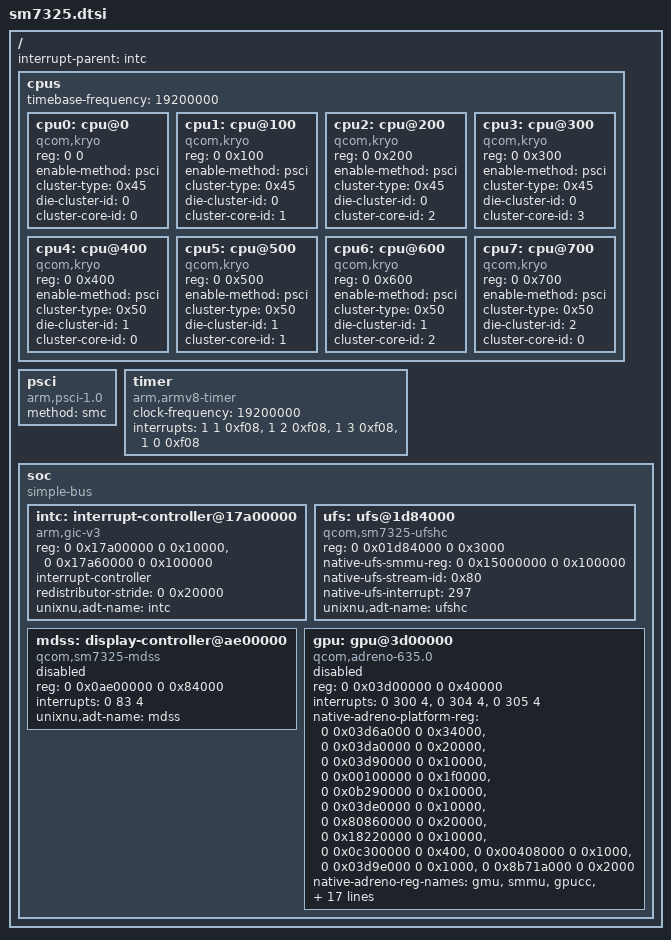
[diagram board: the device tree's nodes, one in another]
// SPDX-License-Identifier: BSD-2-Clause-Patent

/ {
    #address-cells = <2>;
    #size-cells = <2>;
    interrupt-parent = <&intc>;

    cpus {
        #address-cells = <2>;
        #size-cells = <0>;
        timebase-frequency = <19200000>;

        cpu0: cpu@0 {
            device_type = "cpu";
            compatible = "qcom,kryo";
            reg = <0 0>;
            enable-method = "psci";
            cluster-type = <0x45>;
            die-cluster-id = <0>;
            cluster-core-id = <0>;
        };

        cpu1: cpu@100 {
            device_type = "cpu";
            compatible = "qcom,kryo";
            reg = <0 0x100>;
            enable-method = "psci";
            cluster-type = <0x45>;
            die-cluster-id = <0>;
            cluster-core-id = <1>;
        };

        cpu2: cpu@200 {
            device_type = "cpu";
            compatible = "qcom,kryo";
            reg = <0 0x200>;
            enable-method = "psci";
            cluster-type = <0x45>;
            die-cluster-id = <0>;
            cluster-core-id = <2>;
        };

        cpu3: cpu@300 {
            device_type = "cpu";
            compatible = "qcom,kryo";
            reg = <0 0x300>;
            enable-method = "psci";
            cluster-type = <0x45>;
            die-cluster-id = <0>;
            cluster-core-id = <3>;
        };

        cpu4: cpu@400 {
            device_type = "cpu";
            compatible = "qcom,kryo";
            reg = <0 0x400>;
            enable-method = "psci";
            cluster-type = <0x50>;
            die-cluster-id = <1>;
            cluster-core-id = <0>;
        };

        cpu5: cpu@500 {
            device_type = "cpu";
            compatible = "qcom,kryo";
            reg = <0 0x500>;
            enable-method = "psci";
            cluster-type = <0x50>;
            die-cluster-id = <1>;
            cluster-core-id = <1>;
        };

        cpu6: cpu@600 {
            device_type = "cpu";
            compatible = "qcom,kryo";
            reg = <0 0x600>;
            enable-method = "psci";
            cluster-type = <0x50>;
            die-cluster-id = <1>;
            cluster-core-id = <2>;
        };

        cpu7: cpu@700 {
            device_type = "cpu";
            compatible = "qcom,kryo";
            reg = <0 0x700>;
            enable-method = "psci";
            cluster-type = <0x50>;
            die-cluster-id = <2>;
            cluster-core-id = <0>;
        };
    };

    psci {
        compatible = "arm,psci-1.0";
        method = "smc";
    };

    timer {
        compatible = "arm,armv8-timer";
        clock-frequency = <19200000>;
        interrupts = <1 1 0xf08>, <1 2 0xf08>, <1 3 0xf08>, <1 0 0xf08>;
    };

    soc {
        compatible = "simple-bus";
        #address-cells = <2>;
        #size-cells = <2>;
        ranges;

        intc: interrupt-controller@17a00000 {
            compatible = "arm,gic-v3";
            reg = <0 0x17a00000 0 0x10000>, <0 0x17a60000 0 0x100000>;
            #interrupt-cells = <3>;
            interrupt-controller;
            redistributor-stride = <0 0x20000>;
            unixnu,adt-name = "intc";
        };

        ufs: ufs@1d84000 {
            compatible = "qcom,sm7325-ufshc";
            reg = <0 0x01d84000 0 0x3000>;
            native-ufs-smmu-reg = <0 0x15000000 0 0x100000>;
            native-ufs-stream-id = <0x80>;
            native-ufs-interrupt = <297>;
            unixnu,adt-name = "ufshc";
        };

        mdss: display-controller@ae00000 {
            compatible = "qcom,sm7325-mdss";
            reg = <0 0x0ae00000 0 0x84000>;
            interrupts = <0 83 4>;
            unixnu,adt-name = "mdss";
            status = "disabled";
        };

        gpu: gpu@3d00000 {
            compatible = "qcom,adreno-635.0", "qcom,adreno";
            reg = <0 0x03d00000 0 0x40000>;
            reg-names = "gpu";
            interrupts = <0 300 4>, <0 304 4>, <0 305 4>;
            interrupt-names = "gpu", "hfi", "gmu";
            native-adreno-platform-reg =
                <0 0x03d6a000 0 0x34000>,
                <0 0x03da0000 0 0x20000>,
                <0 0x03d90000 0 0x10000>,
                <0 0x00100000 0 0x1f0000>,
                <0 0x0b290000 0 0x10000>,
                <0 0x03de0000 0 0x10000>,
                <0 0x80860000 0 0x20000>,
                <0 0x18220000 0 0x10000>,
                <0 0x0c300000 0 0x400>,
                <0 0x00408000 0 0x1000>,
                <0 0x03d9e000 0 0x1000>,
                <0 0x8b71a000 0 0x2000>;
            native-adreno-reg-names = "gmu", "smmu", "gpucc", "gcc",
                "pdc", "rscc", "command-db", "rpmh", "aop", "ipcc", "cx-misc", "zap";
            native-adreno-chip-id = <0x06030500>;
            native-adreno-gmem-bytes = <0x80000>;
            native-adreno-frequency-hz = <315000000>;
            native-adreno-highest-bank-bit = <14>;
            native-adreno-gpu-bank = <0>;
            native-adreno-gpu-asid = <1>;
            native-adreno-gpu-slot = <0>;
            native-adreno-gpu-sid = <0>;
            native-adreno-gpu-sid-mask = <0x400>;
            native-adreno-gmu-bank = <1>;
            native-adreno-gmu-asid = <2>;
            native-adreno-gmu-slot = <5>;
            native-adreno-gmu-sid = <5>;
            native-adreno-gmu-sid-mask = <0x400>;
            unixnu,adt-name = "adreno";
            status = "disabled";
        };
    };
};
